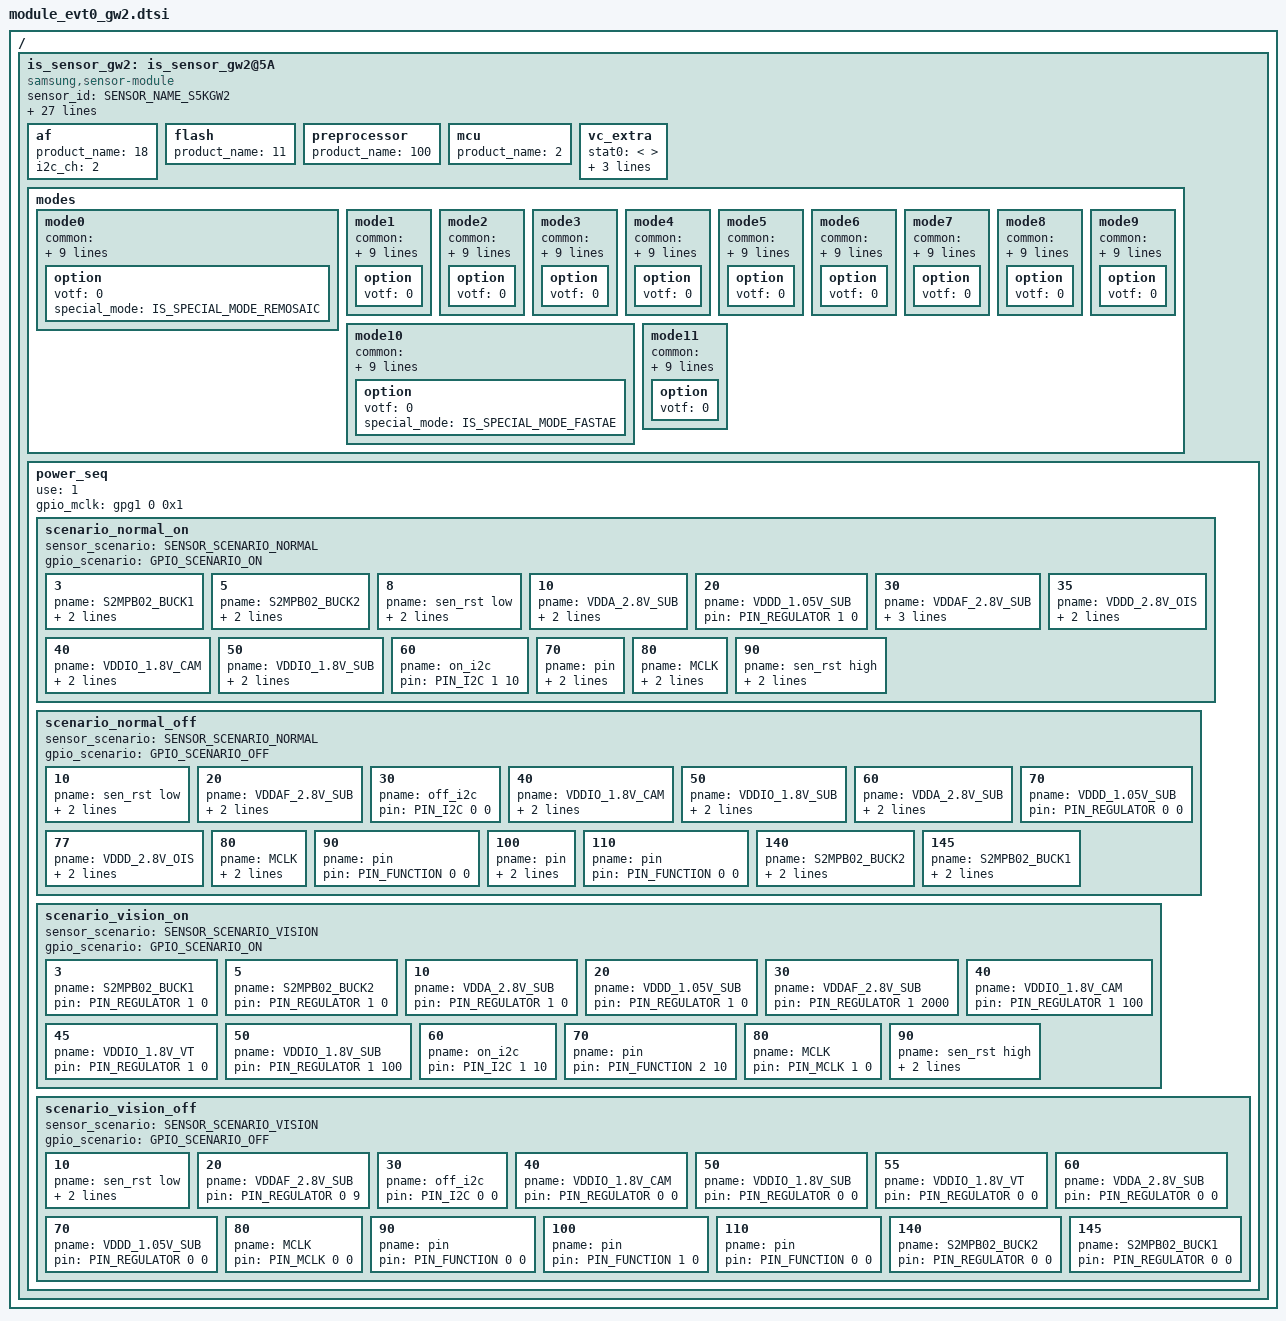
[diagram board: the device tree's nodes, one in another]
/*
 * SAMSUNG EXYNOSxxxx board camera device tree source
 *
 * Copyright (c) 2019 Samsung Electronics Co., Ltd.
 *		http://www.samsung.com
 *
 * This program is free software; you can redistribute it and/or modify
 * it under the terms of the GNU General Public License version 2 as
 * published by the Free Software Foundation.
 */

#include <dt-bindings/camera/exynos_is_dt.h>

/ {
	fragment@camera {
		target-path = "/";
		__overlay__ {
			is_sensor_gw2: is_sensor_gw2@5A {
				compatible = "samsung,sensor-module";

				/* common */
				sensor_id = <SENSOR_NAME_S5KGW2>;
				active_width = <9248>;
				active_height = <6936>;
				margin_left = <0>;
				margin_right = <0>;
				margin_top = <0>;
				margin_bottom = <0>;
				max_framerate = <240>;
				bitwidth = <10>;
				use_retention_mode = <SENSOR_RETENTION_UNSUPPORTED>;
				sensor_maker = "SLSI";
				sensor_name = "S5KGW2";
				setfile_name = "setfile_gw2.bin";

				status = "okay";

				/* board */
				pinctrl-names = "pin0", "pin1", "pin2", "release";
				pinctrl-0 = <>;
				pinctrl-1 = <&sensor_mclk0_out>;
				pinctrl-2 = <&sensor_mclk0_fn>;
				pinctrl-3 = <>;

				position = <2>; /* Rear:0. Front:1, Tele:2 */
				id = <2>; /* is_sensor id */
				mclk_ch = <0>;
				mclk_freq = <19200>;
				sensor_i2c_ch = <1>; /* SENSOR_CONTROL_I2C1 */

				/* vendor */
				rom_type = <2>; /* ROM_TYPE_EEPROM */
				rom_id = <0>;
				rom_cal_index = <1>;
				rom_dualcal_id = <0>;
				rom_dualcal_index = <1>;

				af {
					product_name = <18>; /* ACTUATOR_NAME_AK737X : ak7371 or ak7374 */
					i2c_ch = <2>; /* SENSOR_CONTROL_I2C2 */
				};

				flash {
					product_name = <11>; /* FLASH_GPIO */
				};

				preprocessor {
					product_name = <100>; /* NOTHING */
				};

				mcu {
					product_name = <2>; /* INTERNAL */
				};

				vc_extra {
					/* ex) statX = <stat_type, sensor_mode, max_width, max_height, max_element> */
					stat0 = </* not avaliable */>;			/* VC_BUF_DATA_TYPE_SENSOR_STAT1 */
					stat1 = </*VC_STAT_TYPE_PDP_4_0_PDAF_STAT0*/ 1100 /* VC_SENSOR_MODE_SUPER_PD_3_TAIL */ 405 1160 1736 2>; /* VC_BUF_DATA_TYPE_GENERAL_STAT1 */
					stat2 = </* not avaliable */>;			/* VC_BUF_DATA_TYPE_SENSOR_STAT2 */
					stat3 = </*VC_STAT_TYPE_PDP_4_0_PDAF_STAT1*/ 1101 /* VC_SENSOR_MODE_SUPER_PD_3_TAIL */ 405 1160 1736 2>; /* VC_BUF_DATA_TYPE_GENERAL_STAT2 */
				};

				/* sensor modes */
				modes {
						/* common = <width, height, fps, settle, mode, lane, speed, interleave, lrte, pd_mode> */
						/* vcX = <map, hwformat, width, height, hwformat, type, width, height> */
					mode0 {
						common = <9248 6936 15 0 0 CSI_DATA_LANES_3 2726 CSI_MODE_VC_ONLY LRTE_DISABLE PD_NONE>;
						vc0 = </* in */ 0 HW_FORMAT_RAW10 9248 6936	/* out */ HW_FORMAT_RAW10 VC_NOTHING 9248 6936>;
						vc1 = </* in */ 2 HW_FORMAT_UNKNOWN 0 0		/* out */ HW_FORMAT_UNKNOWN VC_NOTHING 0 0>;
						vc2 = </* in */ 1 HW_FORMAT_RAW10 1152 1720	/* out */ HW_FORMAT_RAW10 VC_NOTHING 0 0>;
						vc3 = </* in */ 3 HW_FORMAT_UNKNOWN 0 0		/* out */ HW_FORMAT_UNKNOWN VC_NOTHING 0 0>;
						option { votf = <0>; special_mode = <IS_SPECIAL_MODE_REMOSAIC>; };
					};
					mode1 {
						common = <7680 4320 30 0 1 CSI_DATA_LANES_3 2726 CSI_MODE_VC_ONLY LRTE_DISABLE PD_MSPD_TAIL>;
						vc0 = </* in */ 0 HW_FORMAT_RAW10 7680 4320	/* out */ HW_FORMAT_RAW10 VC_NOTHING 7680 4320>;
						vc1 = </* in */ 2 HW_FORMAT_UNKNOWN 0 0		/* out */ HW_FORMAT_UNKNOWN VC_NOTHING 0 0>;
						vc2 = </* in */ 1 HW_FORMAT_RAW10_POTF 960 1064	/* out */ HW_FORMAT_RAW10 VC_NOTHING 0 0>;
						vc3 = </* in */ 3 HW_FORMAT_UNKNOWN 0 0		/* out */ HW_FORMAT_UNKNOWN VC_NOTHING 0 0>;
						option { votf = <0>; };
					};
					mode2 {
						common = <4864 3648 30 0 2 CSI_DATA_LANES_3 1091 CSI_MODE_VC_ONLY LRTE_DISABLE PD_MSPD_TAIL>;
						vc0 = </* in */ 0 HW_FORMAT_RAW10 4864 3648 	/* out */ HW_FORMAT_RAW10 VC_NOTHING 4864 3648>;
						vc1 = </* in */ 2 HW_FORMAT_UNKNOWN 0 0     	/* out */ HW_FORMAT_UNKNOWN VC_NOTHING 0 0>;
						vc2 = </* in */ 1 HW_FORMAT_RAW10_POTF 608 904	/* out */ HW_FORMAT_RAW10 VC_NOTHING 0 0>;
						vc3 = </* in */ 3 HW_FORMAT_UNKNOWN 0 0     	/* out */ HW_FORMAT_UNKNOWN VC_NOTHING 0 0>;
						option { votf = <0>; };
					};
					mode3 {
						common = <4864 2736 30 0 3 CSI_DATA_LANES_3 1091 CSI_MODE_VC_ONLY LRTE_DISABLE PD_MSPD_TAIL>;
						vc0 = </* in */ 0 HW_FORMAT_RAW10 4864 2736	/* out */ HW_FORMAT_RAW10 VC_NOTHING 4864 2736>;
						vc1 = </* in */ 2 HW_FORMAT_UNKNOWN 0 0		/* out */ HW_FORMAT_UNKNOWN VC_NOTHING 0 0>;
						vc2 = </* in */ 1 HW_FORMAT_RAW10_POTF 608 680	/* out */ HW_FORMAT_RAW10 VC_NOTHING 0 0>;
						vc3 = </* in */ 3 HW_FORMAT_UNKNOWN 0 0		/* out */ HW_FORMAT_UNKNOWN VC_NOTHING 0 0>;
						option { votf = <0>; };
					};
					mode4 {
						common = <4624 3468 30 0 4 CSI_DATA_LANES_3 2726 CSI_MODE_VC_ONLY LRTE_DISABLE PD_MSPD_TAIL>;
						vc0 = </* in */ 0 HW_FORMAT_RAW10 4624 3468 	/* out */ HW_FORMAT_RAW10 VC_NOTHING 4624 3468>;
						vc1 = </* in */ 2 HW_FORMAT_UNKNOWN 0 0     	/* out */ HW_FORMAT_UNKNOWN VC_NOTHING 0 0>;
						vc2 = </* in */ 1 HW_FORMAT_RAW10_POTF 1152 1712/* out */ HW_FORMAT_RAW10 VC_NOTHING 0 0>;
						vc3 = </* in */ 3 HW_FORMAT_UNKNOWN 0 0     	/* out */ HW_FORMAT_UNKNOWN VC_NOTHING 0 0>;
						option { votf = <0>; };
					};
					mode5{
						common = <4624 2604 30 0 5 CSI_DATA_LANES_3 2726 CSI_MODE_VC_ONLY LRTE_DISABLE PD_MSPD_TAIL>;
						vc0 = </* in */ 0 HW_FORMAT_RAW10 4624 2604	/* out */ HW_FORMAT_RAW10 VC_NOTHING 4624 2604>;
						vc1 = </* in */ 2 HW_FORMAT_UNKNOWN 0 0		/* out */ HW_FORMAT_UNKNOWN VC_NOTHING 0 0>;
						vc2 = </* in */ 1 HW_FORMAT_RAW10_POTF 1152 1280/* out */ HW_FORMAT_RAW10 VC_NOTHING 0 0>;
						vc3 = </* in */ 3 HW_FORMAT_UNKNOWN 0 0		/* out */ HW_FORMAT_UNKNOWN VC_NOTHING 0 0>;
						option { votf = <0>; };
					};
					mode6{
						common = <4624 2604 60 0 6 CSI_DATA_LANES_3 2726 CSI_MODE_VC_ONLY LRTE_DISABLE PD_MSPD_TAIL>;
						vc0 = </* in */ 0 HW_FORMAT_RAW10 4624 2604	/* out */ HW_FORMAT_RAW10 VC_NOTHING 4624 2604>;
						vc1 = </* in */ 2 HW_FORMAT_UNKNOWN 0 0		/* out */ HW_FORMAT_UNKNOWN VC_NOTHING 0 0>;
						vc2 = </* in */ 1 HW_FORMAT_RAW10_POTF 1152 1280/* out */ HW_FORMAT_RAW10 VC_NOTHING 0 0>;
						vc3 = </* in */ 3 HW_FORMAT_UNKNOWN 0 0		/* out */ HW_FORMAT_UNKNOWN VC_NOTHING 0 0>;
						option { votf = <0>; };
					};
					mode7{
						common = <3200 2400 60 0 7 CSI_DATA_LANES_3 2726 CSI_MODE_VC_ONLY LRTE_DISABLE PD_MSPD_TAIL>;
						vc0 = </* in */ 0 HW_FORMAT_RAW10 3200 2400	/* out */ HW_FORMAT_RAW10 VC_NOTHING 3200 2400>;
						vc1 = </* in */ 2 HW_FORMAT_UNKNOWN 0 0		/* out */ HW_FORMAT_UNKNOWN VC_NOTHING 0 0>;
						vc2 = </* in */ 1 HW_FORMAT_RAW10_POTF 400 584	/* out */ HW_FORMAT_RAW10 VC_NOTHING 0 0>;
						vc3 = </* in */ 3 HW_FORMAT_UNKNOWN 0 0		/* out */ HW_FORMAT_UNKNOWN VC_NOTHING 0 0>;
						option { votf = <0>; };
					};
					mode8{
						common = <3200 1800 60 0 8 CSI_DATA_LANES_3 2726 CSI_MODE_VC_ONLY LRTE_DISABLE PD_MSPD_TAIL>;
						vc0 = </* in */ 0 HW_FORMAT_RAW10 3200 1800	/* out */ HW_FORMAT_RAW10 VC_NOTHING 3200 1800>;
						vc1 = </* in */ 2 HW_FORMAT_UNKNOWN 0 0		/* out */ HW_FORMAT_UNKNOWN VC_NOTHING 0 0>;
						vc2 = </* in */ 1 HW_FORMAT_RAW10_POTF 400 440	/* out */ HW_FORMAT_RAW10 VC_NOTHING 0 0>;
						vc3 = </* in */ 3 HW_FORMAT_UNKNOWN 0 0		/* out */ HW_FORMAT_UNKNOWN VC_NOTHING 0 0>;
						option { votf = <0>; };
					};
					mode9{
						common = <2432 1824 30 0 9 CSI_DATA_LANES_3 2726 CSI_MODE_VC_ONLY LRTE_DISABLE PD_MSPD_TAIL>;
						vc0 = </* in */ 0 HW_FORMAT_RAW10 2432 1824	/* out */ HW_FORMAT_RAW10 VC_NOTHING 2432 1824>;
						vc1 = </* in */ 2 HW_FORMAT_UNKNOWN 0 0		/* out */ HW_FORMAT_UNKNOWN VC_NOTHING 0 0>;
						vc2 = </* in */ 1 HW_FORMAT_RAW10_POTF 608 904	/* out */ HW_FORMAT_RAW10 VC_NOTHING 0 0>;
						vc3 = </* in */ 3 HW_FORMAT_UNKNOWN 0 0		/* out */ HW_FORMAT_UNKNOWN VC_NOTHING 0 0>;
						option { votf = <0>; };
					};
					mode10 {
						common = <1920 1080 120 0 10 CSI_DATA_LANES_3 2236 CSI_MODE_VC_ONLY LRTE_DISABLE PD_NONE>;
						vc0 = </* in */ 0 HW_FORMAT_RAW10 1920 1080	/* out */ HW_FORMAT_RAW10 VC_NOTHING 1920 1080>;
						vc1 = </* in */ 2 HW_FORMAT_UNKNOWN 0 0		/* out */ HW_FORMAT_UNKNOWN VC_NOTHING 0 0>;
						vc2 = </* in */ 1 HW_FORMAT_UNKNOWN 0 0		/* out */ HW_FORMAT_UNKNOWN VC_NOTHING 0 0>;
						vc3 = </* in */ 3 HW_FORMAT_UNKNOWN 0 0		/* out */ HW_FORMAT_UNKNOWN VC_NOTHING 0 0>;
						option { votf = <0>; special_mode = <IS_SPECIAL_MODE_FASTAE>; };
					};
					mode11 {
						common = <1920 1080 240 0 11 CSI_DATA_LANES_3 2236 CSI_MODE_VC_ONLY LRTE_DISABLE PD_NONE>;
						vc0 = </* in */ 0 HW_FORMAT_RAW10 1920 1080	/* out */ HW_FORMAT_RAW10 VC_NOTHING 1920 1080>;
						vc1 = </* in */ 2 HW_FORMAT_UNKNOWN 0 0		/* out */ HW_FORMAT_UNKNOWN VC_NOTHING 0 0>;
						vc2 = </* in */ 1 HW_FORMAT_UNKNOWN 0 0		/* out */ HW_FORMAT_UNKNOWN VC_NOTHING 0 0>;
						vc3 = </* in */ 3 HW_FORMAT_UNKNOWN 0 0		/* out */ HW_FORMAT_UNKNOWN VC_NOTHING 0 0>;
						option { votf = <0>; };
					};
				};

				power_seq {
					use = <1>;
					gpio_mclk = <&gpg1 0 0x1>;

					scenario_normal_on {
						sensor_scenario = <SENSOR_SCENARIO_NORMAL>;
						gpio_scenario = <GPIO_SCENARIO_ON>;

						/* A start node number should be over the 10 for reserved number 0~9. */
						/* pname = "name"; pin = <act value dealy voltage>; gpio = <gpx# # 0x1>; */
						3 { pname = "S2MPB02_BUCK1"; pin = <PIN_REGULATOR 1 0>; share = <SRT_ACQUIRE SHARED_PIN9 1>; };
						5 { pname = "S2MPB02_BUCK2"; pin = <PIN_REGULATOR 1 0>; share = <SRT_ACQUIRE SHARED_PIN5 1>; };
						8 { pname = "sen_rst low"; pin = <PIN_OUTPUT 0 0>; gpio = <&gpp7 3 0x1>; };
						10 { pname = "VDDA_2.8V_SUB"; pin = <PIN_REGULATOR 1 0>; share = <SRT_ACQUIRE SHARED_PIN8 1>; };
						20 { pname = "VDDD_1.05V_SUB"; pin = <PIN_REGULATOR 1 0>; };
						30 { pname = "VDDAF_2.8V_SUB"; pin = <PIN_REGULATOR 1 0>; share = <SRT_ACQUIRE SHARED_PIN4 1>; actuator_i2c_delay = <10000>; };
						35 { pname = "VDDD_2.8V_OIS"; pin = <PIN_REGULATOR 1 0>; share = <SRT_ACQUIRE SHARED_PIN3 1>; };
						40 { pname = "VDDIO_1.8V_CAM"; pin = <PIN_REGULATOR 1 0>; share = <SRT_ACQUIRE SHARED_PIN2 1>; };
						50 { pname = "VDDIO_1.8V_SUB"; pin = <PIN_REGULATOR 1 0>; share = <SRT_ACQUIRE SHARED_PIN7 1>; };
						60 { pname = "on_i2c"; pin = <PIN_I2C 1 10>; };
						70 { pname = "pin"; pin = <PIN_FUNCTION 2 0>; share = <SRT_ACQUIRE SHARED_PIN1 1>; };
						80 { pname = "MCLK"; pin = <PIN_MCLK 1 0>; share = <SRT_ACQUIRE SHARED_PIN0 1>; };
						90 { pname = "sen_rst high"; pin = <PIN_OUTPUT 1 10000>; gpio = <&gpp7 3 0x1>; };
					};

					scenario_normal_off {
						sensor_scenario = <SENSOR_SCENARIO_NORMAL>;
						gpio_scenario = <GPIO_SCENARIO_OFF>;

						/* A start node number should be over the 10 for reserved number 0~9. */
						/* pname = "name"; pin = <act value dealy voltage>; gpio = <gpx# # 0x1>; */
						10 { pname = "sen_rst low"; pin = <PIN_OUTPUT 0 0>; gpio = <&gpp7 3 0x1>; };
						20 { pname = "VDDAF_2.8V_SUB"; pin = <PIN_REGULATOR 0 0>; share = <SRT_RELEASE SHARED_PIN4 0>; };
						30 { pname = "off_i2c"; pin = <PIN_I2C 0 0>; };
						40 { pname = "VDDIO_1.8V_CAM"; pin = <PIN_REGULATOR 0 0>; share = <SRT_RELEASE SHARED_PIN2 0>; };
						50 { pname = "VDDIO_1.8V_SUB"; pin = <PIN_REGULATOR 0 0>; share = <SRT_RELEASE SHARED_PIN7 0>; };
						60 { pname = "VDDA_2.8V_SUB"; pin = <PIN_REGULATOR 0 0>; share = <SRT_RELEASE SHARED_PIN8 0>; };
						70 { pname = "VDDD_1.05V_SUB"; pin = <PIN_REGULATOR 0 0>; };
						77 { pname = "VDDD_2.8V_OIS"; pin = <PIN_REGULATOR 0 0>; share = <SRT_RELEASE SHARED_PIN3 0>; };
						80 { pname = "MCLK"; pin = <PIN_MCLK 0 0>; share = <SRT_RELEASE SHARED_PIN0 0>; };
						90 { pname = "pin"; pin = <PIN_FUNCTION 0 0>; };
						100 { pname = "pin"; pin = <PIN_FUNCTION 1 0>; share = <SRT_RELEASE SHARED_PIN1 0>; };
						110 { pname = "pin"; pin = <PIN_FUNCTION 0 0>; };
						140 { pname = "S2MPB02_BUCK2"; pin = <PIN_REGULATOR 0 0>; share = <SRT_RELEASE SHARED_PIN5 0>; };
						145 { pname = "S2MPB02_BUCK1"; pin = <PIN_REGULATOR 0 0>; share = <SRT_RELEASE SHARED_PIN9 0>; };
					};

					scenario_vision_on {
						sensor_scenario = <SENSOR_SCENARIO_VISION>;
						gpio_scenario = <GPIO_SCENARIO_ON>;

						/* A start node number should be over the 10 for reserved number 0~9. */
						/* pname = "name"; pin = <act value dealy voltage>; gpio = <gpx# # 0x1>; */
						3 { pname = "S2MPB02_BUCK1"; pin = <PIN_REGULATOR 1 0>; };
						5 { pname = "S2MPB02_BUCK2"; pin = <PIN_REGULATOR 1 0>; };
						10 { pname = "VDDA_2.8V_SUB"; pin = <PIN_REGULATOR 1 0>; };
						20 { pname = "VDDD_1.05V_SUB"; pin = <PIN_REGULATOR 1 0>; };
						30 { pname = "VDDAF_2.8V_SUB"; pin = <PIN_REGULATOR 1 2000>; };
						40 { pname = "VDDIO_1.8V_CAM"; pin = <PIN_REGULATOR 1 100>; };
						45 { pname = "VDDIO_1.8V_VT"; pin = <PIN_REGULATOR 1 0>; };
						50 { pname = "VDDIO_1.8V_SUB"; pin = <PIN_REGULATOR 1 100>; };
						60 { pname = "on_i2c"; pin = <PIN_I2C 1 10>; };
						70 { pname = "pin"; pin = <PIN_FUNCTION 2 10>; };
						80 { pname = "MCLK"; pin = <PIN_MCLK 1 0>; };
						90 { pname = "sen_rst high"; pin = <PIN_OUTPUT 1 8000>; gpio = <&gpp7 3 0x1>; };
					};

					scenario_vision_off {
						sensor_scenario = <SENSOR_SCENARIO_VISION>;
						gpio_scenario = <GPIO_SCENARIO_OFF>;

						/* A start node number should be over the 10 for reserved number 0~9. */
						/* pname = "name"; pin = <act value dealy voltage>; gpio = <gpx# # 0x1>; */
						10 { pname = "sen_rst low"; pin = <PIN_OUTPUT 0 0>; gpio = <&gpp7 3 0x1>; };
						20 { pname = "VDDAF_2.8V_SUB"; pin = <PIN_REGULATOR 0 9>; };
						30 { pname = "off_i2c"; pin = <PIN_I2C 0 0>; };
						40 { pname = "VDDIO_1.8V_CAM"; pin = <PIN_REGULATOR 0 0>; };
						50 { pname = "VDDIO_1.8V_SUB"; pin = <PIN_REGULATOR 0 0>; };
						55 { pname = "VDDIO_1.8V_VT"; pin = <PIN_REGULATOR 0 0>; };
						60 { pname = "VDDA_2.8V_SUB"; pin = <PIN_REGULATOR 0 0>; };
						70 { pname = "VDDD_1.05V_SUB"; pin = <PIN_REGULATOR 0 0>; };
						80 { pname = "MCLK"; pin = <PIN_MCLK 0 0>; };
						90 { pname = "pin"; pin = <PIN_FUNCTION 0 0>; };
						100 { pname = "pin"; pin = <PIN_FUNCTION 1 0>; };
						110 { pname = "pin"; pin = <PIN_FUNCTION 0 0>; };
						140 { pname = "S2MPB02_BUCK2"; pin = <PIN_REGULATOR 0 0>; };
						145 { pname = "S2MPB02_BUCK1"; pin = <PIN_REGULATOR 0 0>; };
					};
				};
			};
		}; /* end of __overlay__ */
	}; /* end of fragment */
}; /* end of root */
